# EQEP1_REG register map
Vendor: Texas Instruments
Peripheral module from a debugger description file (folder J721S2).
Registers are 32-bit, read-write, reset 0x0 unless marked. A register's access mark holds for its fields unless they carry their own. Offsets are as the file gives them; lines under a group give offsets from that group; [hi:lo] are bit positions; {n}, {i} and the like mark numbered series; 'fields as' and 'values as' point back to an identical list; <NAME> marks a mode.

## EQEP1_REG
0x00 REG_QPOSCNT
  [31:0] POSCNT — This 32-bit position counter register counts up/down on every QEP pulse based on direction input. This counter acts as a position integrator whose count value is proportional to position from a give reference point.
0x04 REG_QPOSINIT
  [31:0] INITPOS — This register contains the position value to be used to initialize the position counter based on external strobe or Index event. Position counter can be initialized through software.
0x08 REG_QPOSMAX
  [31:0] MAXPOS — This register contains the maximum Position counter value for error checking in index reset mode or to reset the Position counter based on the maximum count value.
0x0C REG_QPOSCMP
  [31:0] POSCMP — Position compare value in this register is compared with the position counter (POSCNT) to optionally generate interrupt on compare match.
0x10 REG_QPOSILAT ro
  [31:0] IPOSLAT — Position counter value can be latched into this register on index event.
0x14 REG_QPOSSLAT ro
  [31:0] SPOSLAT — Position counter value can be latched into this register on strobe event.
0x18 REG_QPOSLAT ro
  [31:0] POSLAT — Position counter value can be latched into this register on unit time out event.
0x1C REG_QUTMR
  [31:0] UNITTMR — This register acts as time base for unit time event generation. When this timer value matches with unit time period value, unit time event is generated.
0x20 REG_QUPRD
  [31:0] UNITPRD — This register contains the period count for unit timer to generate periodic unit time events to latch the QEP position information at periodic interval & optionally to generate interrupt.
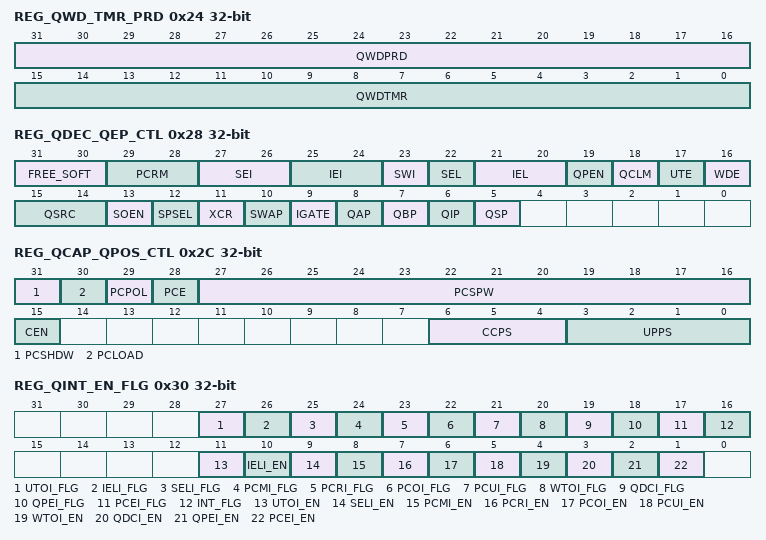
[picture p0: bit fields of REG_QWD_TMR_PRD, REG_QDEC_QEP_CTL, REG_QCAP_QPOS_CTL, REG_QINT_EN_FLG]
0x24 REG_QWD_TMR_PRD
  [31:16] QWDPRD — This field contains the time-out count for the QEP peripheral watch dog timer. When watch dog timer value matches with the watch dog period value, status flag is set to indicate the stall.
  [15:0] QWDTMR — This field acts as time base for watch dog to detect stalls. When this timer value matches with watch dog period value, watch dog timeout event is generated. This register is reset upon edge transition in Quadrature clock indicating the motion.
0x28 REG_QDEC_QEP_CTL
  [31:30] FREE_SOFT — POSCNT Behavior: 00 Position Counter stops immediately on emulation suspend 01 Position Counter continues to count until the rollover 1x Position Counter is unaffected by emulation suspend QWDTMR Behavior: 02 Watchdog counter stops immediately 03 Watchdog counter counts until WD period match roll over 1x Watchdog counter is unaffected by emulation suspend UNITTMR Behavior: 02 Unit timer stops immediately 03 Unit timer counts until period rollover 1x Unit timer is unaffected by emulation suspend QCTMR Behavior: 00 Capture Timer stops immediately 01 Capture Timer counts until next unit period event 1x Capture Timer is unaffected by emulation suspend
  [29:28] PCRM — Position Counter Reset mode: 0,0 Index event resets the Position Counter for each revolution 0,1 Maximum position event resets the Position Counter. 1,0 RESET ONCE: First Index Event resets the Position Counter 1,1 Unit Time event resets the Position Counter
  [27:26] SEI — Strobe Event Initialization of Position Counter: 0,x Do nothing (action disabled) 1,0 Initialize Position Counter on rising edge of QEPS signal 1,1 Clockwise Direction: Initialize Position Counter on Rising edge of QEPS strobe Counter Clockwise Direction: Initialize Position Counter on Falling edge of QEPS strobe
  [25:24] IEI — Index Event Initialization of Position Counter: 0,x Do nothing (action disabled) 1,0 Initialize Position Counter on rising edge of index signal 1,1 Initialize Position Counter on falling edge of index signal
  [23] SWI — Software Initialization of Position Counter: 0 Do nothing (action disabled) 1 Initialize Position Counter, this bit is cleared automatically
  [22] SEL — Strobe Event Latch of Position Counter: 0 Latch Position Counter on rising edge of strobe signal 1 Clockwise Direction: Position Counter is latched on Rising edge of QEPS strobe Counter Clockwise Direction: Position Counter is latched on Falling edge of QEPS strobe
  [21:20] IEL — Index Event Latch of Position Counter (Software Index Marker): 0,0 Reserved 0,1 Latch Position Counter on Rising edge of index signal 1,0 Latch Position Counter on Falling edge of index signal 1,1 Software Index Marker Latch the Position Counter & Quadrature direction flag on index event marker. Position counter is latched to IPOSLAT register & direction flag is latched in QEPSTS:QDLF bit.
  [19] QPEN — Quadrature Position counter Enable/Software Reset: 0 Software Reset Initialize the internal operating Flag/read only registers to reset value* Following register are reset & QEP control registers retains the same value on the software reset be disturbed IPOSLAT, SPOSLAT, POSLAT, QCTMRLAT, QCPRDLAT, QEPSTS 1 QEP Position counter is enabled
  [18] QCLM — QEP Capture Latch mode: 0 Latch on Position Counter read by CPU: Capture Timer & Capture Period values are latched into QCTMRLAT & QCPRDLAT registers when CPU reads the POSCNT register. 1 Latch on Unit Time Out: Position Counter, Capture Timer & Capture Period values are latched into POSLAT, QCTMRLAT & QCPRDLAT registers on Unit time out
  [17] UTE — QEP Unit Timer Enable: 0 Disable QEP Unit Timer 1 Enable Unit Timer
  [16] WDE — QEP Watchdog Enable: 0 Disable QEP watchdog 1 Enable QEP watchdog
  [15:14] QSRC — Position Counter Source selection: 00 Quadrature Count mode (QCLK=iCLK, QDIR=iDIR) 01 Direction Count mode (QCLK=xCLK, QDIR=xDIR) 10 UP Count mode for Frequency measurement (QCLK=xCLK, QDIR=1) 11 DOWN Count mode for Frequency measurement (QCLK=xCLK, QDIR=0)
  [13] SOEN — Enable Position Compare Sync Output: 0 Disable Position Compare Sync Output 1 Enable Position Compare Sync Output
  [12] SPSEL — Sync Output Pin Selection: 0 Index pin is used for Sync output (see Note below) 1 Strobe pin is used for Sync output (see Note below)
  [11] XCR — External Clock Rate: 0 2x Resolution: Count the rising/falling edge 1 1x Resolution: Count the rising edge only
  [10] SWAP — CLK/DIR signal source for Position Counter: 0 Quadrature clock inputs are not swapped 1 Quadrature clock inputs are swapped
  [9] IGATE — Index Pulse Gating Option: 0 Disable gating of Index pulse 1 Gate the index pin with strobe
  [8] QAP — QEPA input Polarity: 0 No effect 1 Negate QEPA input
  [7] QBP — QEPB input Polarity: 0 No effect 1 Negate QEPB input
  [6] QIP — QEPI input Polarity: 0 No effect 1 Negate QEPI input
  [5] QSP — QEPS input Polarity: 0 No effect 1 Negate QEPS input
0x2C REG_QCAP_QPOS_CTL
  [31] PCSHDW — Position Compare Shadow Enable: 0 Shadow disabled, load Immediate 1 Shadow Enabled.
  [30] PCLOAD — Position Compare Shadow Load Mode: 0 Load On POSCNT = 0 1 Load When POSCNT = POSCMP
  [29] PCPOL — Polarity Of Sync Output: 0 Active HIGH pulse output 1 Active LOW pulse output
  [28] PCE — Position Compare Enable/Disable: 0 Disable Mode (no inter or pulse) 1 Enable Mode
  [27:16] PCSPW — Select pulse width period in SYSCLKOUT cycles: 0x000 1 * 4 * SYSCLKOUT cycles 0x001 2 * 4 * SYSCLKOUT cycles ... 0xFFF 4096 * 4 * SYSCLKOUT cycles
  [15] CEN — Enable QEP Capture: 0 QEP Capture unit is disabled 1 QEP Capture unit is enabled
  [6:4] CCPS — QEP Capture timer clock prescalar: 000 CAPCLK=SYSCLKOUT/1 001 CAPCLK=SYSCLKOUT/2 010 CAPCLK=SYSCLKOUT/4 011 CAPCLK=SYSCLKOUT/8 100 CAPCLK=SYSCLKOUT/16 101 CAPCLK=SYSCLKOUT/32 110 CAPCLK=SYSCLKOUT/64 111 CAPCLK=SYSCLKOUT/128
  [3:0] UPPS — Unit Position Event prescalar: 0000 UPEVNT = QCLK/1 0001 UPEVNT = QCLK/2 0010 UPEVNT = QCLK/4 0011 UPEVNT = QCLK/8 0100 UPEVNT = QCLK/16 0101 UPEVNT = QCLK/32 0110 UPEVNT = QCLK/64 0111 UPEVNT = QCLK/128 1000 UPEVNT = QCLK/256 1001 UPEVNT = QCLK/512 1010 UPEVNT = QCLK/1024 1011 UPEVNT = QCLK/2048 11xx Reserved
0x30 REG_QINT_EN_FLG access per field
  [27] UTOI_FLG ro — Unit Time Out Interrupt Flag: 0 Reading a 0 indicates no interrupt generated 1 Set by QEP unit timer period match
  [26] IELI_FLG ro — Index Event Latch Interrupt Flag: 0 Reading a 0 indicates no interrupt generated 1 This bit is set after latching the POSCNT to IPOSLAT
  [25] SELI_FLG ro — Strobe Event Latch Interrupt Flag: 0 Reading a 0 indicates no interrupt generated 1 This bit is set after latching the POSCNT to SPOSLAT
  [24] PCMI_FLG ro — QEP Compare Match Event Interrupt Flag: 0 Reading a 0 indicates no interrupt generated 1 This bit is set on position compare match
  [23] PCRI_FLG ro — Position Compare Ready Interrupt Flag: 0 Reading a 0 indicates no interrupt generated 1 This bit is set on position compare FIFO level match
  [22] PCOI_FLG ro — Position Counter Overflow Interrupt Flag: 0 Reading a 0 indicates no interrupt generated 1 This bit is set during the POSCNT overflow
  [21] PCUI_FLG ro — Position Counter Underflow Interrupt Flag: 0 Reading a 0 indicates no interrupt generated 1 This bit is set during the POSCNT underflow
  [20] WTOI_FLG ro — Watchdog Timeout Interrupt Flag: 0 Reading a 0 indicates no interrupt generated 1 Set by watch dog (monitoring QEPA & QEPB) timeout
  [19] QDCI_FLG ro — Quadrature Direction Change Interrupt Flag: 0 Reading a 0 indicates no interrupt generated 1 This bit is set during change of direction
  [18] QPEI_FLG ro — Quadrature Phase Error Interrupt Flag: 0 Reading a 0 indicates no interrupt generated 1 Set on simultaneous transition of QEPA & QEPB
  [17] PCEI_FLG ro — Position Counter Error Interrupt Flag: 0 Reading a 0 indicates no interrupt generated 1 This is set during error in position count between index
  [16] INT_FLG ro — Global Interrupt Status Flag: Reading a 1 on this bit indicates that an interrupt was generated from one of the following events. Reading a 0 indicates no interrupt generated.
  [11] UTOI_EN rw — Unit Time Out Interrupt Enable: 0 Interrupt is disabled 1 Interrupt is enabled
  [10] IELI_EN rw — Index Event Latch Interrupt Enable: 0 Interrupt is disabled 1 Interrupt is enabled
  [9] SELI_EN rw — Strobe Event Latch Interrupt Enable: 0 Interrupt is disabled 1 Interrupt is enabled
  [8] PCMI_EN rw — Position Compare Match Interrupt Enable: 0 Interrupt is disabled 1 Interrupt is enabled
  [7] PCRI_EN rw — Position Compare Ready Interrupt Enable: 0 Interrupt is disabled 1 Interrupt is enabled
  [6] PCOI_EN rw — Position Counter Overflow Interrupt Enable: 0 Interrupt is disabled 1 Interrupt is enabled
  [5] PCUI_EN rw — Position Counter Underflow Interrupt Enable: 0 Interrupt is disabled 1 Interrupt is enabled
  [4] WTOI_EN rw — Watchdog Time Out Interrupt Enable: 0 Interrupt is disabled 1 Interrupt is enabled
  [3] QDCI_EN rw — Quadrature Direction Change Interrupt Enable: 0 Interrupt is disabled 1 Interrupt is enabled
  [2] QPEI_EN rw — Quadrature Phase Error Interrupt Enable: 0 Interrupt is disabled 1 Interrupt is enabled
  [1] PCEI_EN rw — Position Counter Error Interrupt Enable: 0 Interrupt is disabled 1 Interrupt is enabled
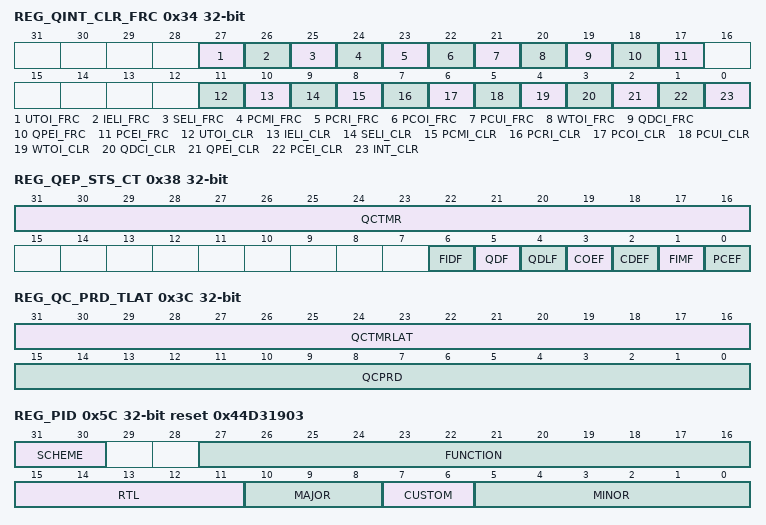
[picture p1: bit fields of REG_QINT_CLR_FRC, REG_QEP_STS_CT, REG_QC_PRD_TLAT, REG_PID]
0x34 REG_QINT_CLR_FRC access not given
  [27] UTOI_FRC — Unit Time Out Interrupt Force: 0 No effect 1 Force the interrupt (access W1TS)
  [26] IELI_FRC — Index Event Latch Interrupt Force: 0 No effect 1 Force the interrupt (access W1TS)
  [25] SELI_FRC — Strobe Event Latch Interrupt Force: 0 No effect 1 Force the interrupt (access W1TS)
  [24] PCMI_FRC — Position Compare Match Interrupt Force: 0 No effect 1 Force the interrupt (access W1TS)
  [23] PCRI_FRC — Position Compare Ready Interrupt Force: 0 No effect 1 Force the interrupt (access W1TS)
  [22] PCOI_FRC — Position Counter Overflow Interrupt Force: 0 No effect 1 Force the interrupt (access W1TS)
  [21] PCUI_FRC — Position Counter Underflow Interrupt Force: 0 No effect 1 Force the interrupt (access W1TS)
  [20] WTOI_FRC — Watchdog Time Out Interrupt Force: 0 No effect 1 Force the interrupt (access W1TS)
  [19] QDCI_FRC — Quadrature Direction Change Interrupt Force: 0 No effect 1 Force the interrupt (access W1TS)
  [18] QPEI_FRC — Quadrature Phase Error Interrupt Force: 0 No effect 1 Force the interrupt (access W1TS)
  [17] PCEI_FRC — Position Counter Error Interrupt Force: 0 No effect 1 Force the interrupt (access W1TS)
  [11] UTOI_CLR — Clear Unit Time Out Interrupt Flag: Writing 1 clears the interrupt flag (access W1TC)
  [10] IELI_CLR — Clear Index Event Latch Interrupt Flag: Writing 1 clears the interrupt flag (access W1TC)
  [9] SELI_CLR — Clear Strobe Event Latch Interrupt Flag: Writing 1 clears the interrupt flag (access W1TC)
  [8] PCMI_CLR — Clear QEP Compare Match Event Interrupt Flag: Writing 1 clears the interrupt flag (access W1TC)
  [7] PCRI_CLR — Clear Position Compare Ready Interrupt Flag: Writing 1 clears the interrupt flag (access W1TC)
  [6] PCOI_CLR — Clear Position Counter Overflow Interrupt Flag: Writing 1 clears the interrupt flag (access W1TC)
  [5] PCUI_CLR — Clear Position Counter Underflow Interrupt Flag: Writing 1 clears the interrupt flag (access W1TC)
  [4] WTOI_CLR — Clear Watchdog Timeout Interrupt Flag: Writing 1 clears the interrupt flag (access W1TC)
  [3] QDCI_CLR — Clear Quadrature Direction Change Interrupt Flag: Writing 1 clears the interrupt flag (access W1TC)
  [2] QPEI_CLR — Clear Quadrature Phase Error Interrupt Flag: Writing 1 clears the interrupt flag (access W1TC)
  [1] PCEI_CLR — Clear Position Counter Error Interrupt Flag: Writing 1 clears the interrupt flag (access W1TC)
  [0] INT_CLR — Global Interrupt Clear Flag: Writing a 1 will clear the interrupt flag and enable further interrupts to be generated if any of the event flags are set to 1. (access W1TC)
0x38 REG_QEP_STS_CT access not given
  [31:16] QCTMR rw — This field provides time base for edge capture unit.
  [6] FIDF ro — Direction on First Index Marker: Status of the direction is latched on first index event marker
  [5] QDF ro — Quadrature Direction flag: 0 Anti-clockwise rotation or Reverse movement 1 Clockwise rotation or Forward movement
  [4] QDLF ro — QEP Direction Latch Flag: Status of Direction is latched on every index event marker.
  [3] COEF — Capture Overflow Error Flag: 0 Sticky bit, cleared by writing 1 1 Overflow occurred in QEP Capture timer (QEPCTMR) (access R/W1TC)
  [2] CDEF — Capture Direction Error Flag: 0 Sticky bit, cleared by writing 1 1 Direction change occurred between the capture position event (access R/W1TC)
  [1] FIMF — First Index Marker Flag: 0 Sticky bit, cleared by writing 1 1 Set by first occurrence of index pulse (access R/W1TC)
  [0] PCEF ro — Position Counter Error Flag: (This bit is not sticky bit & it is updated for every index event) 0 No error occurred during the last index transition 1 Position counter error
0x3C REG_QC_PRD_TLAT access per field
  [31:16] QCTMRLAT ro — QEP Capture timer value can be latched into this register on two events viz., Unit Timeout event, Reading the QEP position counter.
  [15:0] QCPRD rw — This field holds the period count value between the last successive QEP position events.
0x40 REG_QCPRDLAT ro
  [15:0] QCPRDLAT — QEP Capture period value can be latched into this register on two events viz., Unit Timeout event, Reading the QEP position counter.
0x5C REG_PID ro reset 0x44D31903
  [31:30] SCHEME, [27:16] FUNCTION, [15:11] RTL, [10:8] MAJOR, [7:6] CUSTOM, [5:0] MINOR
